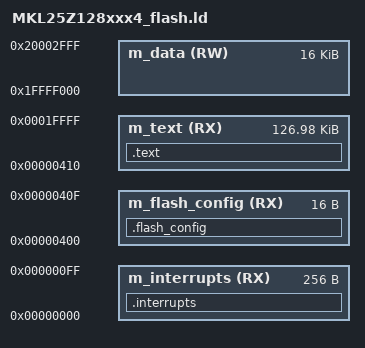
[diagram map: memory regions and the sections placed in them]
/* Linker file for GNU C Compiler */

/* Specify the memory areas */
MEMORY
{
  m_interrupts          (RX)  : ORIGIN = 0x00000000, LENGTH = 0x00000100
  m_flash_config        (RX)  : ORIGIN = 0x00000400, LENGTH = 0x00000010
  m_text                (RX)  : ORIGIN = 0x00000410, LENGTH = 0x0001FBF0
  m_data                (RW)  : ORIGIN = 0x1FFFF000, LENGTH = 0x00004000
}

/* Define output sections */
SECTIONS
{
  /* The startup code goes first into internal flash */
  .interrupts :
  {
    __VECTOR_TABLE = .;
    . = ALIGN(4);
    KEEP(*(.isr_vector))     /* Startup code */
    . = ALIGN(4);
  } > m_interrupts


  .flash_config :
  {
    . = ALIGN(4);
    KEEP(*(.FlashConfig))    /* Flash Configuration Field (FCF) */
    . = ALIGN(4);
  } > m_flash_config

  /* The program code and other data goes into internal flash */
  .text :
  {
    . = ALIGN(4);
    *(.text)                 /* .text sections (code) */
    *(.text*)                /* .text* sections (code) */
    *(.rodata)               /* .rodata sections (constants, strings, etc.) */
    *(.rodata*)              /* .rodata* sections (constants, strings, etc.) */
    *(.glue_7)               /* glue arm to thumb code */
    *(.glue_7t)              /* glue thumb to arm code */
    *(.eh_frame)
    KEEP (*(.init))
    KEEP (*(.fini))
    . = ALIGN(4);
  } > m_text

  .ARM.attributes 0 : { *(.ARM.attributes) }
}
